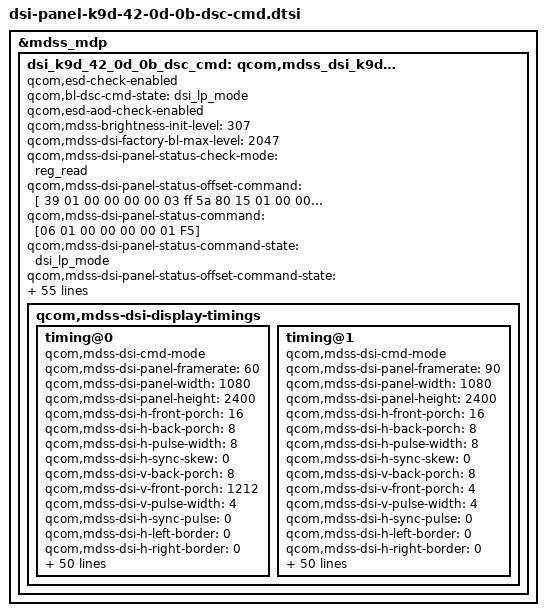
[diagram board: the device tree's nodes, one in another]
&mdss_mdp {
	dsi_k9d_42_0d_0b_dsc_cmd: qcom,mdss_dsi_k9d_42_0d_0b_dsc_cmd {
		qcom,esd-check-enabled;
		qcom,bl-dsc-cmd-state = "dsi_lp_mode";
		qcom,esd-aod-check-enabled;
		qcom,mdss-brightness-init-level = <307>;
		qcom,mdss-dsi-factory-bl-max-level = <2047>;
		qcom,mdss-dsi-panel-status-check-mode = "reg_read";
		qcom,mdss-dsi-panel-status-offset-command = [
			39 01 00 00 00 00 03 ff 5a 
			80 15 01 00 00 00 00 02 65 37];
		qcom,mdss-dsi-panel-status-command = [06 01 00 00 00 00 01 F5];
		qcom,mdss-dsi-panel-status-command-state = "dsi_lp_mode";
		qcom,mdss-dsi-panel-status-offset-command-state = "dsi_lp_mode";
		qcom,mdss-dsi-panel-status-value = <0 0 0>;
		qcom,mdss-dsi-panel-status-read-length = <3>;
		qcom,mdss-dsi-panel-name = "xiaomi 42 0d 0b cmd mode dsc dsi panel";
//		qcom,mdss-dsi-panel-peak-brightness = <4200000>;
		qcom,mdss-dsi-panel-type = "dsi_cmd_mode";
		qcom,mdss-dsi-virtual-channel-id = <0>;
		qcom,mdss-dsi-stream = <0>;
		qcom,mdss-dsi-bpp = <24>;
		qcom,mdss-dsi-color-order = "rgb_swap_rgb";
		qcom,mdss-dsi-underflow-color = <0xff>;
		qcom,mdss-dsi-border-color = <0>;

		qcom,dsi-ctrl-num = <0>;
		qcom,dsi-phy-num = <0>;

		qcom,mdss-dsi-traffic-mode = "burst_mode";
		qcom,mdss-dsi-lane-map = "lane_map_0123";
		qcom,mdss-dsi-bllp-eof-power-mode;
		qcom,mdss-dsi-bllp-power-mode;
		qcom,mdss-dsi-lane-0-state;
		qcom,mdss-dsi-lane-1-state;
		qcom,mdss-dsi-lane-2-state;
		qcom,mdss-dsi-lane-3-state;
		qcom,mdss-dsi-dma-trigger = "trigger_sw";
		qcom,mdss-dsi-mdp-trigger = "none";
		qcom,mdss-dsi-reset-sequence =  <1 6>, <0 1>, <1 11>;
		qcom,mdss-pan-physical-width-dimension = <695>;
		qcom,mdss-pan-physical-height-dimension = <1545>;
		qcom,mdss-dsi-te-pin-select = <1>;
		qcom,mdss-dsi-wr-mem-start = <0x2c>;
		qcom,mdss-dsi-wr-mem-continue = <0x3c>;
		qcom,mdss-factory-brightness-max-level = <2047>;
		qcom,mdss-dsi-te-dcs-command = <1>;
		qcom,mdss-dsi-te-check-enable;
		qcom,mdss-dsi-te-using-te-pin;
		qcom,mdss-dsi-tx-eot-append;
		qcom,mdss-dsi-lp11-init;

		qcom,mdss-dsi-bl-inverted-dbv;
		qcom,bl-update-flag = "delay_until_first_frame";

		qcom,mdss-dsi-panel-hdr-enabled;
		qcom,mdss-dsi-panel-hdr-color-primaries = <14500 15500 32000 17000 15500 30000 8000 3000>;
		qcom,mdss-dsi-panel-peak-brightness = <4200000>;
		qcom,mdss-dsi-panel-blackness-level = <3230>;

		qcom,mdss-dsi-display-timings {
			timing@0{
				qcom,mdss-dsi-cmd-mode;
				qcom,mdss-dsi-panel-framerate = <60>;
				qcom,mdss-dsi-panel-width = <1080>;
				qcom,mdss-dsi-panel-height = <2400>;
				qcom,mdss-dsi-h-front-porch = <16>;
				qcom,mdss-dsi-h-back-porch = <8>;
				qcom,mdss-dsi-h-pulse-width = <8>;
				qcom,mdss-dsi-h-sync-skew = <0>;
				qcom,mdss-dsi-v-back-porch = <8>;
				qcom,mdss-dsi-v-front-porch = <1212>;
				qcom,mdss-dsi-v-pulse-width = <4>;
				qcom,mdss-dsi-h-sync-pulse = <0>;
				qcom,mdss-dsi-h-left-border = <0>;
				qcom,mdss-dsi-h-right-border = <0>;
				qcom,mdss-dsi-v-top-border = <0>;
				qcom,mdss-dsi-v-bottom-border = <0>;
				qcom,mdss-dsi-panel-clockrate = <652000000>;
				qcom,mdss-dsi-panel-jitter = <0x5 0x1>;
				qcom,mdss-mdp-transfer-time-us = <15700>;
				qcom,mdss-dsi-on-command = [
					15 01 00 00 00 00 02 03 01
					39 01 00 00 00 00 03 f0 aa 10
					39 01 00 00 00 00 06 cf 09 07 8b 89 1f
					39 01 00 00 00 00 08 b1 01 ec 00 18 04 e0 00
					39 01 00 00 00 00 03 44 00 03
					39 01 00 00 00 00 03 f0 aa 12
					39 01 00 00 00 00 03 c1 00 0f
					05 01 00 00 00 00 02 35 00 15
					01 00 00 00 00 02 53 20 15 01
					00 00 00 00 02 59 09
					39 01 00 00 00 00 03 51 07 ff
					15 01 00 00 00 00 02 6c 00 15
					01 00 00 00 00 02 6f 02
					39 01 00 00 00 00 03 f0 aa 14
					39 01 00 00 00 00 03 b2 03 33
					39 01 00 00 00 00 0d b4 0a 56
					00 00 0a 56 00 00 0a 56 00 00
					39 01 00 00 00 00 0a b5 00 17 17 17 17 17 17 06 01
					39 01 00 00 00 00 07 b9 00 00 0a 17 17 17
					39 01 00 00 00 00 0c bc 10 00 00 0a 11 17 69 17 69 17 69
					39 01 00 00 00 00 0c be 10 10 00 0a 22 17 41 17 41 17 41
					39 01 00 00 00 00 03 ff 5a 81
					15 01 00 00 00 00 02 65 05
					15 01 00 00 00 00 02 f3 0f
					39 01 00 00 00 00 03 f0 aa 10
					39 01 00 00 00 00 02 b3 c7
					39 01 00 00 00 00 03 f0 aa 00
					39 01 00 00 00 00 03 ff 5a 00
					05 01 00 00 c8 00 02 11 00
					05 01 00 00 00 00 02 29 00];
				qcom,mdss-dsi-off-command = [
					05 01 00 00 14 00 02 28 00
					05 01 00 00 78 00 02 10 00];
				qcom,mdss-dsi-on-command-state = "dsi_lp_mode";
				qcom,mdss-dsi-off-command-state = "dsi_lp_mode";

				qcom,mdss-dsi-timing-switch-command = [
					15 01 00 00 0C 00 02 6C 00];
				qcom,mdss-dsi-timing-switch-command-state = "dsi_lp_mode";

				qcom,mdss-dsi-nolp-command = [
					05 01 00 00 00 00 01
					38 15 01 00 00 00 00 02 6c 00];
				qcom,mdss-dsi-nolp-command-state = "dsi_lp_mode";

				qcom,compression-mode = "dsc";
				qcom,mdss-dsc-version = <0x11>;
				qcom,mdss-dsc-scr-version = <0x0>;
				qcom,mdss-dsc-slice-height = <12>;
				qcom,mdss-dsc-slice-width = <1080>;
				qcom,mdss-dsc-slice-per-pkt = <1>;
				qcom,mdss-dsc-bit-per-component = <10>;
				qcom,mdss-dsc-bit-per-pixel = <8>;
				qcom,mdss-dsc-block-prediction-enable;
			};

			timing@1{
				qcom,mdss-dsi-cmd-mode;
				qcom,mdss-dsi-panel-framerate = <90>;
				qcom,mdss-dsi-panel-width = <1080>;
				qcom,mdss-dsi-panel-height = <2400>;
				qcom,mdss-dsi-h-front-porch = <16>;
				qcom,mdss-dsi-h-back-porch = <8>;
				qcom,mdss-dsi-h-pulse-width = <8>;
				qcom,mdss-dsi-h-sync-skew = <0>;
				qcom,mdss-dsi-v-back-porch = <8>;
				qcom,mdss-dsi-v-front-porch = <4>;
				qcom,mdss-dsi-v-pulse-width = <4>;
				qcom,mdss-dsi-h-sync-pulse = <0>;
				qcom,mdss-dsi-h-left-border = <0>;
				qcom,mdss-dsi-h-right-border = <0>;
				qcom,mdss-dsi-v-top-border = <0>;
				qcom,mdss-dsi-v-bottom-border = <0>;
				qcom,mdss-dsi-panel-clockrate = <652000000>;
				qcom,mdss-dsi-panel-jitter = <0x5 0x1>;
				qcom,mdss-mdp-transfer-time-us = <15700>;
				qcom,mdss-dsi-on-command = [
					15 01 00 00 00 00 02 03 01
					39 01 00 00 00 00 03 f0 aa 10
					39 01 00 00 00 00 06 cf 09 07 8b 89 1f
					39 01 00 00 00 00 08 b1 01 ec 00 18 04 e0 00
					39 01 00 00 00 00 03 44 00 03
					39 01 00 00 00 00 03 f0 aa 12
					39 01 00 00 00 00 03 c1 00 0f
					05 01 00 00 00 00 02 35 00
					15 01 00 00 00 00 02 53 20
					15 01 00 00 00 00 02 59 09
					39 01 00 00 00 00 03 51 07 ff
					15 01 00 00 00 00 02 6c 01
					15 01 00 00 00 00 02 6f 02
					39 01 00 00 00 00 03 f0 aa 14
					39 01 00 00 00 00 03 b2 03 33
					39 01 00 00 00 00 0d b4 0a 56 00 00 0a 56 00 00 0a 56 00 00
					39 01 00 00 00 00 0a b5 00 17 17 17 17 17 17 06 01
					39 01 00 00 00 00 07 b9 00 00 0a 17 17 17
					39 01 00 00 00 00 0c bc 10 00 00 0a 11 17 69 17 69 17 69
					39 01 00 00 00 00 0c be 10 10 00 0a 22 17 41 17 41 17 41
					39 01 00 00 00 00 03 ff 5a 81
					15 01 00 00 00 00 02 65 05
					15 01 00 00 00 00 02 f3 0f
					39 01 00 00 00 00 03 f0 aa 10
					39 01 00 00 00 00 02 b3 c7
					39 01 00 00 00 00 03 f0 aa 00
					39 01 00 00 00 00 03 ff 5a 00
					05 01 00 00 c8 00 02 11 00
					05 01 00 00 00 00 02 29 00];
				qcom,mdss-dsi-off-command = [
					05 01 00 00 14 00 02 28 00
					05 01 00 00 78 00 02 10 00];
				qcom,mdss-dsi-on-command-state = "dsi_lp_mode";
				qcom,mdss-dsi-off-command-state = "dsi_lp_mode";

				qcom,mdss-dsi-timing-switch-command = [
					15 01 00 00 0C 00 02 6C 01];
				qcom,mdss-dsi-timing-switch-command-state = "dsi_lp_mode";

				qcom,mdss-dsi-nolp-command = [
					05 01 00 00 00 00 01 38 15
					01 00 00 00 00 02 6c 00];
				qcom,mdss-dsi-nolp-command-state = "dsi_lp_mode";

				qcom,compression-mode = "dsc";
				qcom,mdss-dsc-version = <0x11>;
				qcom,mdss-dsc-scr-version = <0x0>;
				qcom,mdss-dsc-slice-height = <12>;
				qcom,mdss-dsc-slice-width = <1080>;
				qcom,mdss-dsc-slice-per-pkt = <1>;
				qcom,mdss-dsc-bit-per-component = <10>;
				qcom,mdss-dsc-bit-per-pixel = <8>;
				qcom,mdss-dsc-block-prediction-enable;
			};
		};
	};
};

&dsi_k9d_42_0d_0b_dsc_cmd {
	mi,panel-id = "K9D", "B";
	mi,hbm-51-ctl-flag;
	mi,hbm-off-51-index = <1>;
	mi,hbm-on-51-index = <1>;
	mi,max-brightness-clone = <4095>;
	mi,hbm-bl-min-level = <1>;
	mi,hbm-bl-max-level = <2047>;
	mi,panel-on-dimming-delay = <120>;
	mi,panel-status-check-interval = <2000>;
	mi,thermal-dimming-flag;
	mi,fp-display-on-optimize-flag;

	/* IRQF_ONESHOT | IRQF_TRIGGER_FALLING */
	mi,esd-err-irq-gpio = <&tlmm 3 8196>;

	qcom,mdss-dsi-display-timings {
		timing@0{
			mi,mdss-dsc-panel-id = "K9D", "B";
			mi,mdss-dsi-dimmingon-command = [15 01 00 00 00 00 02 53 28];
			mi,mdss-dsi-dimmingon-command-state = "dsi_hs_mode";
			mi,mdss-dsi-dimmingoff-command = [15 01 00 00 00 00 02 53 20];
			mi,mdss-dsi-dimmingoff-command-state = "dsi_hs_mode";

			mi,mdss-dsi-hbm-on-command = [
				15 01 00 00 00 00 02 53 28
				39 01 00 00 00 00 05 51 0F FF 00 00];
			mi,mdss-dsi-hbm-off-command = [
				15 01 00 00 00 00 02 53 28
				39 01 00 00 00 00 05 51 07 FF 00 00];
			mi,mdss-dsi-hbm-on-command-state = "dsi_lp_mode";
			mi,mdss-dsi-hbm-off-command-state = "dsi_lp_mode";

			mi,mdss-dsi-doze-hbm-command = [
				15 01 00 00 11 00 02 6c 00
				05 01 00 00 14 00 01 39
				15 01 00 00 00 00 02 6d 00];
			mi,mdss-dsi-doze-lbm-command = [
				15 01 00 00 11 00 02 6c 00
				05 01 00 00 14 00 01 39
				15 01 00 00 00 00 02 6d 01];
			mi,mdss-dsi-doze-hbm-command-state = "dsi_lp_mode";
			mi,mdss-dsi-doze-lbm-command-state = "dsi_lp_mode";
		};
		timing@1 {
			mi,mdss-dsc-panel-id = "K9D", "B";
			mi,mdss-dsi-dimmingon-command = [15 01 00 00 00 00 02 53 28];
			mi,mdss-dsi-dimmingon-command-state = "dsi_hs_mode";
			mi,mdss-dsi-dimmingoff-command = [15 01 00 00 00 00 02 53 20];
			mi,mdss-dsi-dimmingoff-command-state = "dsi_hs_mode";

			mi,mdss-dsi-hbm-on-command = [
				15 01 00 00 00 00 02 53 28
				39 01 00 00 00 00 05 51 0F FF 00 00];
			mi,mdss-dsi-hbm-off-command = [
				15 01 00 00 00 00 02 53 28
				39 01 00 00 00 00 05 51 07 FF 00 00];
			mi,mdss-dsi-hbm-on-command-state = "dsi_lp_mode";
			mi,mdss-dsi-hbm-off-command-state = "dsi_lp_mode";

			mi,mdss-dsi-doze-hbm-command = [
				15 01 00 00 00 00 02 2F 01
				39 01 00 00 00 00 05 51 00 00 0F FF
				39 01 00 00 00 00 06 F0 55 AA 52 08 00
				15 01 00 00 00 00 02 B2 08
				05 01 00 00 14 00 01 39
				15 01 00 00 00 00 02 65 01];
			mi,mdss-dsi-doze-lbm-command = [
				15 01 00 00 00 00 02 2F 01
				39 01 00 00 00 00 05 51 00 00 01 55
				39 01 00 00 00 00 06 F0 55 AA 52 08 00
				15 01 00 00 00 00 02 B2 08
				05 01 00 00 14 00 01 39
				15 01 00 00 00 00 02 65 01];
			mi,mdss-dsi-doze-hbm-command-state = "dsi_lp_mode";
			mi,mdss-dsi-doze-lbm-command-state = "dsi_lp_mode";
		};
	};
};
